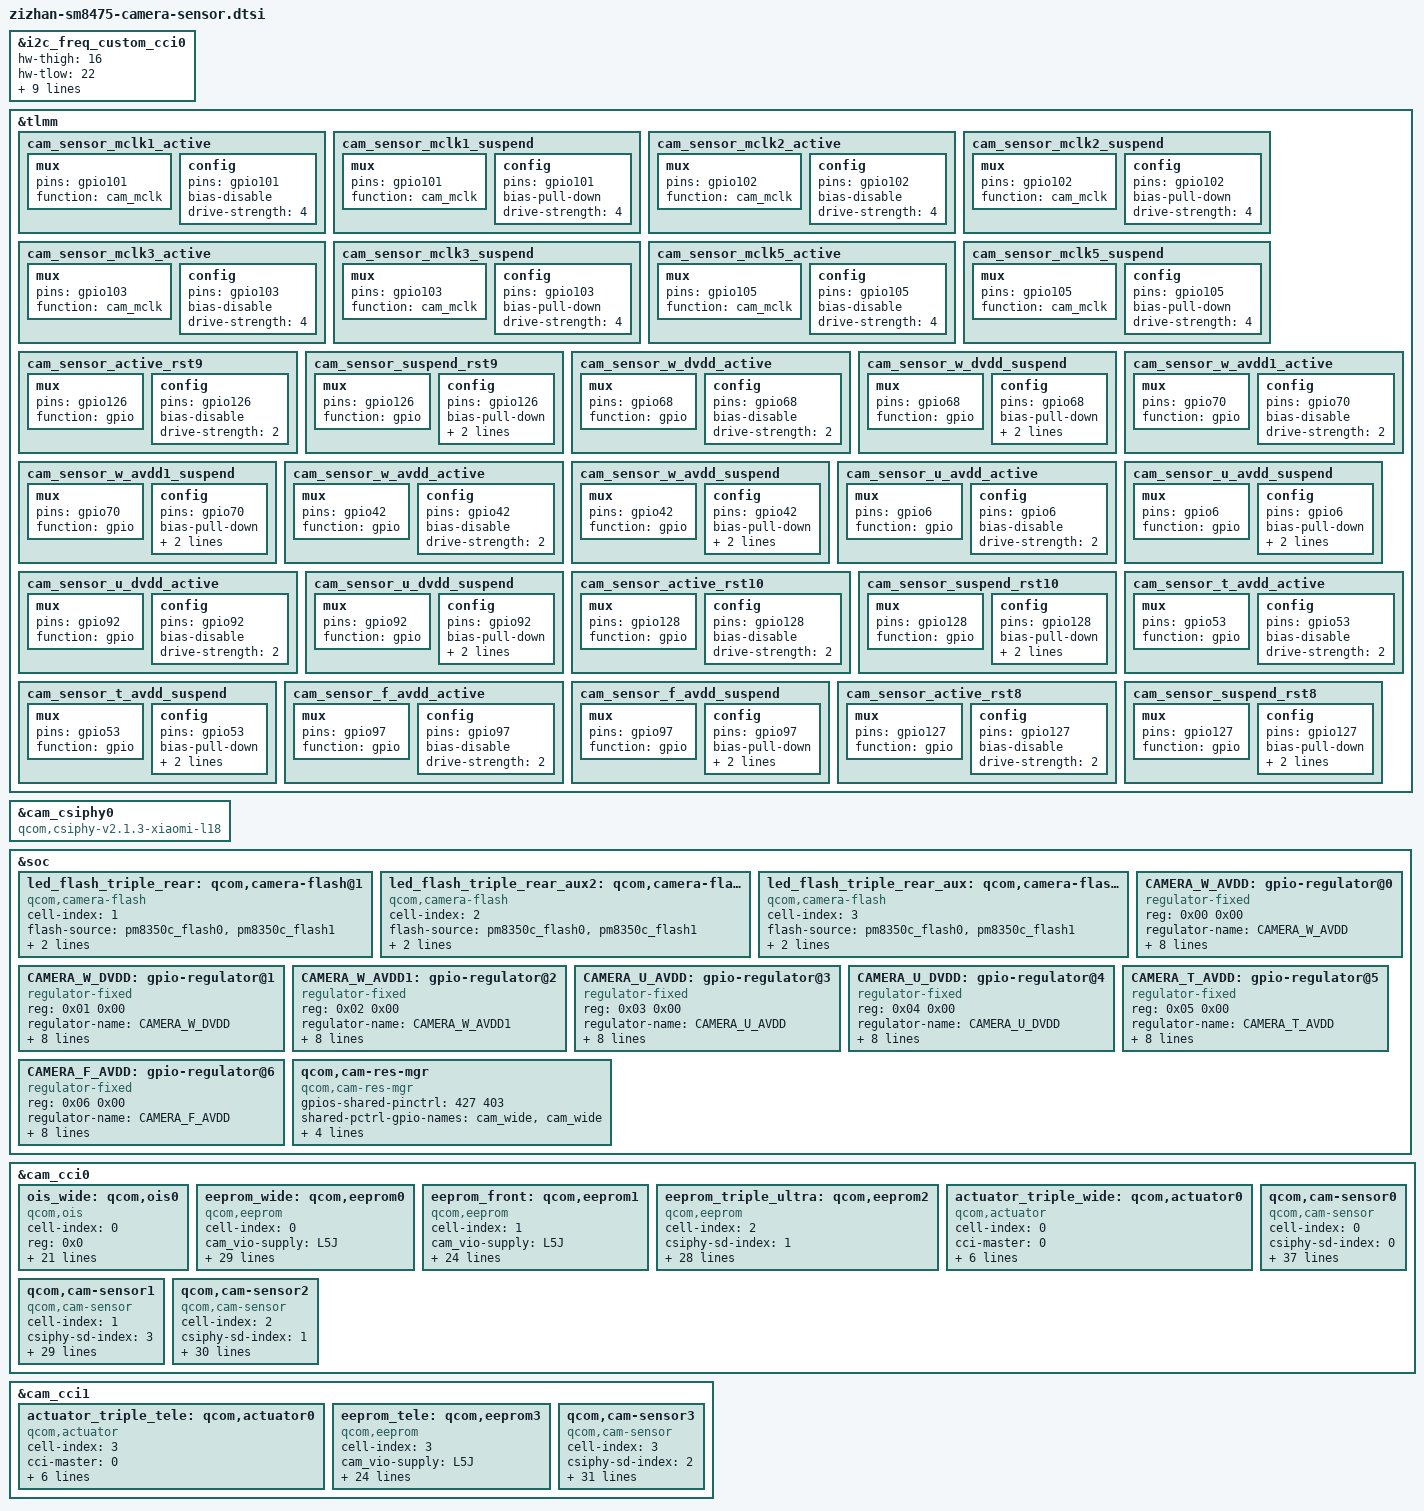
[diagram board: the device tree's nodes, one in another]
#include <dt-bindings/clock/qcom,camcc-waipio.h>

&i2c_freq_custom_cci0 {
	hw-thigh = <16>;
	hw-tlow = <22>;
	hw-tsu-sto = <17>;
	hw-tsu-sta = <18>;
	hw-thd-dat = <16>;
	hw-thd-sta = <15>;
	hw-tbuf = <24>;
	hw-scl-stretch-en = <1>;
	hw-trdhld = <3>;
	hw-tsp = <3>;
	cci-clk-src = <37500000>;
	status = "ok";
};

&tlmm {
//ultra
	cam_sensor_mclk1_active: cam_sensor_mclk1_active {
		/* MCLK1 */
		mux {
			pins = "gpio101";
			function = "cam_mclk";
		};

		config {
			pins = "gpio101";
			bias-disable; /* No PULL */
			drive-strength = <4>; /* 4 MA */
		};
	};

	cam_sensor_mclk1_suspend: cam_sensor_mclk1_suspend {
		/* MCLK1 */
		mux {
			pins = "gpio101";
			function = "cam_mclk";
		};

		config {
			pins = "gpio101";
			bias-pull-down; /* PULL DOWN */
			drive-strength = <4>; /* 4 MA */
		};
	};
//wide
	cam_sensor_mclk2_active: cam_sensor_mclk2_active {
		/* MCLK2 */
		mux {
			pins = "gpio102";
			function = "cam_mclk";
		};

		config {
			pins = "gpio102";
			bias-disable; /* No PULL */
			drive-strength = <4>; /* 4 MA */
		};
	};

	cam_sensor_mclk2_suspend: cam_sensor_mclk2_suspend {
		/* MCLK2 */
		mux {
			pins = "gpio102";
			function = "cam_mclk";
		};

		config {
			pins = "gpio102";
			bias-pull-down; /* PULL DOWN */
			drive-strength = <4>; /* 4 MA */
		};
	};
//tele
	cam_sensor_mclk3_active: cam_sensor_mclk3_active {
		/* MCLK3 */
		mux {
			pins = "gpio103";
			function = "cam_mclk";
		};

		config {
			pins = "gpio103";
			bias-disable; /* No PULL */
			drive-strength = <4>; /* 4 MA */
		};
	};

	cam_sensor_mclk3_suspend: cam_sensor_mclk3_suspend {
		/* MCLK3 */
		mux {
			pins = "gpio103";
			function = "cam_mclk";
		};

		config {
			pins = "gpio103";
			bias-pull-down; /* PULL DOWN */
			drive-strength = <4>; /* 4 MA */
		};
	};
//front
	cam_sensor_mclk5_active: cam_sensor_mclk5_active {
		/* MCLK5 */
		mux {
			pins = "gpio105";
			function = "cam_mclk";
		};

		config {
			pins = "gpio105";
			bias-disable; /* No PULL */
			drive-strength = <4>; /* 4 MA */
		};
	};

	cam_sensor_mclk5_suspend: cam_sensor_mclk5_suspend {
		/* MCLK5 */
		mux {
			pins = "gpio105";
			function = "cam_mclk";
		};

		config {
			pins = "gpio105";
			bias-pull-down; /* PULL DOWN */
			drive-strength = <4>; /* 4 MA */
		};
	};

//wide reset
	cam_sensor_active_rst9: cam_sensor_active_rst9 {
		/* RESET FRONT */
		mux {
			pins = "gpio126";
			function = "gpio";
		};

		config {
			pins = "gpio126";
			bias-disable; /* No PULL */
			drive-strength = <2>; /* 2 MA */
		};
	};

	cam_sensor_suspend_rst9: cam_sensor_suspend_rst9 {
		/* RESET FRONT */
		mux {
			pins = "gpio126";
			function = "gpio";
		};

		config {
			pins = "gpio126";
			bias-pull-down; /* PULL DOWN */
			drive-strength = <2>; /* 2 MA */
			output-low;
		};
	};

//wide dvdd
	cam_sensor_w_dvdd_active: cam_sensor_w_dvdd_active {
		/* SENSOR WIDE DVDD ENABLE */
		mux {
			pins = "gpio68";
			function = "gpio";
		};

		config {
			pins = "gpio68";
			bias-disable; /* No PULL */
			drive-strength = <2>; /* 2 MA */
		};
	};

	cam_sensor_w_dvdd_suspend: cam_sensor_w_dvdd_suspend {
		/* SENSOR WIDE DVDD DISABLE */
		mux {
			pins = "gpio68";
			function = "gpio";
		};

		config {
			pins = "gpio68";
			bias-pull-down; /* PULL DOWN */
			drive-strength = <2>; /* 2 MA */
			output-low;
		};
	};
//wide avdd1
	cam_sensor_w_avdd1_active: cam_sensor_w_avdd1_active {
		/* SENSOR WIDE DVDD ENABLE */
		mux {
			pins = "gpio70";
			function = "gpio";
		};

		config {
			pins = "gpio70";
			bias-disable; /* No PULL */
			drive-strength = <2>; /* 2 MA */
		};
	};

	cam_sensor_w_avdd1_suspend: cam_sensor_w_avdd1_suspend {
		/* SENSOR WIDE DVDD DISABLE */
		mux {
			pins = "gpio70";
			function = "gpio";
		};

		config {
			pins = "gpio70";
			bias-pull-down; /* PULL DOWN */
			drive-strength = <2>; /* 2 MA */
			output-low;
		};
	};

//wide avdd
	cam_sensor_w_avdd_active: cam_sensor_w_avdd_active {
		/* SENSOR WIDE DVDD ENABLE */
		mux {
			pins = "gpio42";
			function = "gpio";
		};

		config {
			pins = "gpio42";
			bias-disable; /* No PULL */
			drive-strength = <2>; /* 2 MA */
		};
	};

	cam_sensor_w_avdd_suspend: cam_sensor_w_avdd_suspend {
		/* SENSOR WIDE DVDD DISABLE */
		mux {
			pins = "gpio42";
			function = "gpio";
		};

		config {
			pins = "gpio42";
			bias-pull-down; /* PULL DOWN */
			drive-strength = <2>; /* 2 MA */
			output-low;
		};
	};

//ultra avdd
cam_sensor_u_avdd_active: cam_sensor_u_avdd_active {
		/* SENSOR WIDE DVDD ENABLE */
		mux {
			pins = "gpio6";
			function = "gpio";
		};

		config {
			pins = "gpio6";
			bias-disable; /* No PULL */
			drive-strength = <2>; /* 2 MA */
		};
	};

	cam_sensor_u_avdd_suspend: cam_sensor_u_avdd_suspend {
		/* SENSOR WIDE DVDD DISABLE */
		mux {
			pins = "gpio6";
			function = "gpio";
		};

		config {
			pins = "gpio6";
			bias-pull-down; /* PULL DOWN */
			drive-strength = <2>; /* 2 MA */
			output-low;
		};
	};

//ultra dvdd
cam_sensor_u_dvdd_active: cam_sensor_u_dvdd_active {
		/* SENSOR WIDE DVDD ENABLE */
		mux {
			pins = "gpio92";
			function = "gpio";
		};

		config {
			pins = "gpio92";
			bias-disable; /* No PULL */
			drive-strength = <2>; /* 2 MA */
		};
	};

	cam_sensor_u_dvdd_suspend: cam_sensor_u_dvdd_suspend {
		/* SENSOR WIDE DVDD DISABLE */
		mux {
			pins = "gpio92";
			function = "gpio";
		};

		config {
			pins = "gpio92";
			bias-pull-down; /* PULL DOWN */
			drive-strength = <2>; /* 2 MA */
			output-low;
		};
	};
//tele reset
	cam_sensor_active_rst10: cam_sensor_active_rst10 {
		/* RESET FRONT */
		mux {
			pins = "gpio128";
			function = "gpio";
		};

		config {
			pins = "gpio128";
			bias-disable; /* No PULL */
			drive-strength = <2>; /* 2 MA */
		};
	};

	cam_sensor_suspend_rst10: cam_sensor_suspend_rst10 {
		/* RESET FRONT */
		mux {
			pins = "gpio128";
			function = "gpio";
		};

		config {
			pins = "gpio128";
			bias-pull-down; /* PULL DOWN */
			drive-strength = <2>; /* 2 MA */
			output-low;
		};
	};
//tele avdd
	cam_sensor_t_avdd_active: cam_sensor_t_avdd_active {
		/* SENSOR WIDE DVDD ENABLE */
		mux {
			pins = "gpio53";
			function = "gpio";
		};

		config {
			pins = "gpio53";
			bias-disable; /* No PULL */
			drive-strength = <2>; /* 2 MA */
		};
	};

	cam_sensor_t_avdd_suspend: cam_sensor_t_avdd_suspend {
		/* SENSOR WIDE DVDD DISABLE */
		mux {
			pins = "gpio53";
			function = "gpio";
		};

		config {
			pins = "gpio53";
			bias-pull-down; /* PULL DOWN */
			drive-strength = <2>; /* 2 MA */
			output-low;
		};
	};

//front avdd
	cam_sensor_f_avdd_active: cam_sensor_f_avdd_active {
		/* SENSOR FRONT AVDD ENABLE */
		mux {
			pins = "gpio97";
			function = "gpio";
		};

		config {
			pins = "gpio97";
			bias-disable; /* No PULL */
			drive-strength = <2>; /* 2 MA */
		};
	};

	cam_sensor_f_avdd_suspend: cam_sensor_f_avdd_suspend {
		/* SENSOR FRONT AVDD DISABLE */
		mux {
			pins = "gpio97";
			function = "gpio";
		};

		config {
			pins = "gpio97";
			bias-pull-down; /* PULL DOWN */
			drive-strength = <2>; /* 2 MA */
			output-low;
		};
	};

//front reset
	cam_sensor_active_rst8: cam_sensor_active_rst8 {
		/* RESET FRONT */
		mux {
			pins = "gpio127";
			function = "gpio";
		};

		config {
			pins = "gpio127";
			bias-disable; /* No PULL */
			drive-strength = <2>; /* 2 MA */
		};
	};

	cam_sensor_suspend_rst8: cam_sensor_suspend_rst8 {
		/* RESET FRONT */
		mux {
			pins = "gpio127";
			function = "gpio";
		};

		config {
			pins = "gpio127";
			bias-pull-down; /* PULL DOWN */
			drive-strength = <2>; /* 2 MA */
			output-low;
		};
	};
};

&cam_csiphy0{
	compatible = "qcom,csiphy-v2.1.3-xiaomi-l18", "qcom,csiphy";
};

&soc {
	led_flash_triple_rear: qcom,camera-flash@1 {
		cell-index = <1>;
		compatible = "qcom,camera-flash";
		flash-source = <&pm8350c_flash0 &pm8350c_flash1>;
		torch-source = <&pm8350c_torch0 &pm8350c_torch1>;
		switch-source = <&pm8350c_switch2>;
		status = "ok";
	};

	led_flash_triple_rear_aux2: qcom,camera-flash@2 {
		cell-index = <2>;
		compatible = "qcom,camera-flash";
		flash-source = <&pm8350c_flash0 &pm8350c_flash1>;
		torch-source = <&pm8350c_torch0 &pm8350c_torch1>;
		switch-source = <&pm8350c_switch2>;
		status = "ok";
	};

	led_flash_triple_rear_aux: qcom,camera-flash@3 {
		cell-index = <3>;
		compatible = "qcom,camera-flash";
		flash-source = <&pm8350c_flash0 &pm8350c_flash1>;
		torch-source = <&pm8350c_torch0 &pm8350c_torch1>;
		switch-source = <&pm8350c_switch2>;
		status = "ok";
	};

	CAMERA_W_AVDD: gpio-regulator@0 {
		compatible = "regulator-fixed";
		reg = <0x00 0x00>;
		regulator-name = "CAMERA_W_AVDD";
		regulator-min-microvolt = <2800000>;
		regulator-max-microvolt = <2800000>;
		regulator-enable-ramp-delay = <100>;
		enable-active-high;
		gpio = <&tlmm 42 0>;
		pinctrl-names = "default", "sleep";
		pinctrl-0 = <&cam_sensor_w_avdd_active &cam_sensor_w_avdd_suspend>;
		vin-supply = <&BOB>;
	};


	CAMERA_W_DVDD: gpio-regulator@1 {
		compatible = "regulator-fixed";
		reg = <0x01 0x00>;
		regulator-name = "CAMERA_W_DVDD";
		regulator-min-microvolt = <1104000>;
		regulator-max-microvolt = <1104000>;
		regulator-enable-ramp-delay = <100>;
		enable-active-high;
		gpio = <&tlmm 68 0>;
		pinctrl-names = "default", "sleep";
		pinctrl-0 = <&cam_sensor_w_dvdd_active &cam_sensor_w_dvdd_suspend>;
		vin-supply = <&S12B>;
	};

	CAMERA_W_AVDD1: gpio-regulator@2 {
		compatible = "regulator-fixed";
		reg = <0x02 0x00>;
		regulator-name = "CAMERA_W_AVDD1";
		regulator-min-microvolt = <1800000>;
		regulator-max-microvolt = <1800000>;
		regulator-enable-ramp-delay = <100>;
		enable-active-high;
		gpio = <&tlmm 70 0>;
		pinctrl-names = "default", "sleep";
		pinctrl-0 = <&cam_sensor_w_avdd1_active &cam_sensor_w_avdd1_suspend>;
		vin-supply = <&S1C>;
	};

	CAMERA_U_AVDD: gpio-regulator@3 {
		compatible = "regulator-fixed";
		reg = <0x03 0x00>;
		regulator-name = "CAMERA_U_AVDD";
		regulator-min-microvolt = <2800000>;
		regulator-max-microvolt = <2800000>;
		regulator-enable-ramp-delay = <100>;
		enable-active-high;
		gpio = <&tlmm 6 0>;
		pinctrl-names = "default", "sleep";
		pinctrl-0 = <&cam_sensor_u_avdd_active &cam_sensor_u_avdd_suspend>;
		vin-supply = <&BOB>;
	};

	CAMERA_U_DVDD: gpio-regulator@4 {
		compatible = "regulator-fixed";
		reg = <0x04 0x00>;
		regulator-name = "CAMERA_U_DVDD";
		regulator-min-microvolt = <1200000>;
		regulator-max-microvolt = <1200000>;
		regulator-enable-ramp-delay = <100>;
		enable-active-high;
		gpio = <&tlmm 92 0>;
		pinctrl-names = "default", "sleep";
		pinctrl-0 = <&cam_sensor_u_dvdd_active &cam_sensor_u_dvdd_suspend>;
		vin-supply = <&S12B>;
	};

	CAMERA_T_AVDD: gpio-regulator@5 {
		compatible = "regulator-fixed";
		reg = <0x05 0x00>;
		regulator-name = "CAMERA_T_AVDD";
		regulator-min-microvolt = <2800000>;
		regulator-max-microvolt = <2800000>;
		regulator-enable-ramp-delay = <100>;
		enable-active-high;
		gpio = <&tlmm 53 0>;
		pinctrl-names = "default", "sleep";
		pinctrl-0 = <&cam_sensor_t_avdd_active &cam_sensor_t_avdd_suspend>;
		vin-supply = <&BOB>;
	};

	CAMERA_F_AVDD: gpio-regulator@6 {
		compatible = "regulator-fixed";
		reg = <0x06 0x00>;
		regulator-name = "CAMERA_F_AVDD";
		regulator-min-microvolt = <2900000>;
		regulator-max-microvolt = <2900000>;
		regulator-enable-ramp-delay = <100>;
		enable-active-high;
		gpio = <&tlmm 97 0>;
		pinctrl-names = "default", "sleep";
		pinctrl-0 = <&cam_sensor_f_avdd_active &cam_sensor_f_avdd_suspend>;
		vin-supply = <&BOB>;
	};


	//GPIO1 -> 302
	qcom,cam-res-mgr {
		compatible = "qcom,cam-res-mgr";
		gpios-shared-pinctrl = <427 403>;
		shared-pctrl-gpio-names = "cam_wide", "cam_wide";
		pinctrl-names = "cam_wide_active", "cam_wide_suspend";
		pinctrl-0 = <&cam_sensor_active_rst9
				&cam_sensor_mclk2_active>;
		pinctrl-1 = <&cam_sensor_suspend_rst9
				&cam_sensor_mclk2_suspend>;
		status = "ok";
	};
};

&cam_cci0
{
	ois_wide: qcom,ois0 {
		cell-index = <0>;
		reg = <0x0>;
		compatible = "qcom,ois";
		cam_vio-supply = <&L5J>;
		cam_clk-supply = <&cam_cc_titan_top_gdsc>;
		cam_v_custom2-supply = <&L4J>;
		regulator-names = "cam_vio", "cam_clk", "cam_v_custom2";
		rgltr-cntrl-support;
		rgltr-min-voltage = <1800000 0 3104000>;
		rgltr-max-voltage = <1800000 0 3104000>;
		rgltr-load-current = <5000 0 103000>;
		use-shared-clk;
		gpio-no-mux = <0>;
		gpios = <&tlmm 102 0>,
			<&tlmm 126 0>;
		gpio-reset = <1>;
		gpio-req-tbl-num = <0 1>;
		gpio-req-tbl-flags = <1 0>;
		gpio-req-tbl-label = "CAMIF_MCLK2",
					"CAM_RESET9";
		cci-device = <0>;
		cci-master = <0>;
		clocks = <&clock_camcc CAM_CC_MCLK2_CLK>;
		clock-names = "cam_clk";
		clock-cntl-level = "nominal";
		clock-rates = <19200000>;
		status = "ok";
	};

	////wide imx766
	eeprom_wide: qcom,eeprom0 {
		cell-index = <0>;
		compatible = "qcom,eeprom";
		cam_vio-supply = <&L5J>;
		cam_vdig-supply = <&CAMERA_W_DVDD>;
		cam_clk-supply = <&cam_cc_titan_top_gdsc>;
		cam_vana-supply = <&CAMERA_W_AVDD>;
		cam_v_custom1-supply = <&CAMERA_W_AVDD1>;
		cam_v_custom2-supply = <&L4J>;   //OIS VCC
		cam_vaf-supply = <&L3J>;
		cam_vana1-supply = <&S12B>;
		regulator-names = "cam_vio", "cam_vdig",
			"cam_clk", "cam_vana", "cam_v_custom1", "cam_v_custom2", "cam_vaf", "cam_vana1";
		rgltr-cntrl-support;
		rgltr-min-voltage = <1800000 1104000 0 2800000 1800000 3104000 3104000 1224000>;
		rgltr-max-voltage = <1800000 1104000 0 2800000 1800000 3104000 3104000 1400000>;
		rgltr-load-current = <5000 653600 0 57500 6000 103000 120000 2356666>;
		use-shared-clk;
		gpio-no-mux = <0>;
		gpios = <&tlmm 102 0>,
			<&tlmm 126 0>;
		gpio-reset = <1>;
		gpio-req-tbl-num = <0 1>;
		gpio-req-tbl-flags = <1 0>;
		gpio-req-tbl-label = "CAMIF_MCLK2",
					"CAM_RESET9";
		cci-device = <0>;
		cci-master = <0>;
		clocks = <&clock_camcc CAM_CC_MCLK2_CLK>;
		clock-names = "cam_clk";
		clock-cntl-level = "nominal";
		clock-rates = <19200000>;
		status = "ok";
	};

	//front imx596
	eeprom_front: qcom,eeprom1 {
		cell-index = <1>;
		compatible = "qcom,eeprom";
		cam_vio-supply = <&L5J>;
		cam_vdig-supply = <&L2J>;
		cam_clk-supply = <&cam_cc_titan_top_gdsc>;
		cam_vana-supply = <&CAMERA_F_AVDD>;
		regulator-names = "cam_vio", "cam_vdig", "cam_clk", "cam_vana";
		rgltr-cntrl-support;
		rgltr-min-voltage = <1800000 1152000 0 2900000>;
		rgltr-max-voltage = <1800000 1152000 0 2900000>;
		rgltr-load-current = <56000 24000 0 35000>;
		gpio-no-mux = <0>;
		pinctrl-names = "cam_default", "cam_suspend";
		pinctrl-0 = <&cam_sensor_mclk5_active
			&cam_sensor_active_rst8>;
		pinctrl-1 = <&cam_sensor_mclk5_suspend
			&cam_sensor_suspend_rst8>;
		gpios = <&tlmm 105 0>,
			<&tlmm 127 0>;
		gpio-reset = <1>;
		gpio-req-tbl-num = <0 1>;
		gpio-req-tbl-flags = <1 0>;
		gpio-req-tbl-label = "CAMIF_MCLK5", "CAM_RESET8";
		cci-device = <0>;
		cci-master = <1>;
		clocks = <&clock_camcc CAM_CC_MCLK5_CLK>;
		clock-names = "cam_clk";
		clock-cntl-level = "nominal";
		clock-rates = <19200000>;
		status = "ok";
	};

	//ultra ov13b10
	eeprom_triple_ultra: qcom,eeprom2 {
		cell-index = <2>;
		compatible = "qcom,eeprom";
		csiphy-sd-index = <1>;
		sensor-position-roll = <90>;
		sensor-position-pitch = <0>;
		sensor-position-yaw = <180>;
		cam_vio-supply = <&L5J>;
		cam_vdig-supply = <&CAMERA_U_DVDD>;
		cam_clk-supply = <&cam_cc_titan_top_gdsc>;
		cam_vana-supply = <&CAMERA_U_AVDD>;
		regulator-names = "cam_vio", "cam_vdig",
			"cam_clk", "cam_vana";
		rgltr-cntrl-support;
		rgltr-min-voltage = <1800000 1200000 0 2800000>;
		rgltr-max-voltage = <1800000 1200000 0 2800000>;
		rgltr-load-current = <400 78000 0 35700>;
		gpio-no-mux = <0>;
		pinctrl-names = "cam_default", "cam_suspend";
		pinctrl-0 = <&cam_sensor_mclk1_active
			&cam_sensor_active_rst1>;
		pinctrl-1 = <&cam_sensor_mclk1_suspend
			&cam_sensor_suspend_rst1>;
		gpios = <&tlmm 101 0>,
			<&tlmm 24 0>;
		gpio-reset = <1>;
		gpio-req-tbl-num = <0 1>;
		gpio-req-tbl-flags = <1 0>;
		gpio-req-tbl-label = "CAMIF_MCLK1",
					"CAM_RESET1";
		cci-device = <0>;
		cci-master = <1>;
		clocks = <&clock_camcc CAM_CC_MCLK1_CLK>;
		clock-names = "cam_clk";
		clock-cntl-level = "nominal";
		clock-rates = <19200000>;
		status = "ok";
	};

	actuator_triple_wide: qcom,actuator0 {
		cell-index = <0>;
		compatible = "qcom,actuator";
		cci-master = <0>;
		cam_vaf-supply = <&L3J>;
		regulator-names = "cam_vaf";
		rgltr-cntrl-support;
		rgltr-min-voltage = <3104000>;
		rgltr-max-voltage = <3104000>;
		rgltr-load-current = <120000>;
	};

	//wide imx766
	qcom,cam-sensor0 {
		cell-index = <0>;
		compatible = "qcom,cam-sensor";
		csiphy-sd-index = <0>;
		eeprom-src = <&eeprom_wide>;
		actuator-src = <&actuator_triple_wide>;
		ois-src  = <&ois_wide>;
		led-flash-src = <&led_flash_triple_rear>;
		sensor-position-roll = <90>;
		sensor-position-pitch = <0>;
		sensor-position-yaw = <180>;
		cam_vio-supply = <&L5J>;
		cam_vdig-supply = <&CAMERA_W_DVDD>;
		cam_clk-supply = <&cam_cc_titan_top_gdsc>;
		cam_vana-supply = <&CAMERA_W_AVDD>;
		cam_v_custom1-supply = <&CAMERA_W_AVDD1>;
		cam_v_custom2-supply = <&L4J>;   //OIS VCC
		cam_vaf-supply = <&L3J>;
		cam_vana1-supply = <&S12B>;
		regulator-names = "cam_vio", "cam_vdig",
			"cam_clk", "cam_vana", "cam_v_custom1", "cam_v_custom2", "cam_vaf", "cam_vana1";
		rgltr-cntrl-support;
		rgltr-min-voltage = <1800000 1104000 0 2800000 1800000 3104000 3104000 1224000>;
		rgltr-max-voltage = <1800000 1104000 0 2800000 1800000 3104000 3104000 1400000>;
		rgltr-load-current = <5000 653600 0 57500 6000 103000 120000 2356666>;
		use-shared-clk;
		gpio-no-mux = <0>;
		gpios = <&tlmm 102 0>,
			<&tlmm 126 0>;
		gpio-reset = <1>;
		gpio-req-tbl-num = <0 1>;
		gpio-req-tbl-flags = <1 0>;
		gpio-req-tbl-label = "CAMIF_MCLK2",
					"CAM_RESET9";
		cci-device = <0>;
		cci-master = <0>;
		clocks = <&clock_camcc CAM_CC_MCLK2_CLK>;
		clock-names = "cam_clk";
		clock-cntl-level = "nominal";
		clock-rates = <19200000>;
		status = "ok";
	};

	//front imx596
	qcom,cam-sensor1 {
		cell-index = <1>;
		compatible = "qcom,cam-sensor";
		csiphy-sd-index = <3>;
		eeprom-src = <&eeprom_front>;
		sensor-position-roll = <270>;
		sensor-position-pitch = <0>;
		sensor-position-yaw = <0>;
		cam_vio-supply = <&L5J>;
		cam_vdig-supply = <&L2J>;
		cam_clk-supply = <&cam_cc_titan_top_gdsc>;
		cam_vana-supply = <&CAMERA_F_AVDD>;
		regulator-names = "cam_vio", "cam_vdig", "cam_clk", "cam_vana";
		rgltr-cntrl-support;
		rgltr-min-voltage = <1800000 1152000 0 2900000>;
		rgltr-max-voltage = <1800000 1152000 0 2900000>;
		rgltr-load-current = <56000 24000 0 35000>;
		gpio-no-mux = <0>;
		pinctrl-names = "cam_default", "cam_suspend";
		pinctrl-0 = <&cam_sensor_mclk5_active
			&cam_sensor_active_rst8>;
		pinctrl-1 = <&cam_sensor_mclk5_suspend
			&cam_sensor_suspend_rst8>;
		gpios = <&tlmm 105 0>,
			<&tlmm 127 0>;
		gpio-reset = <1>;
		gpio-req-tbl-num = <0 1>;
		gpio-req-tbl-flags = <1 0>;
		gpio-req-tbl-label = "CAMIF_MCLK5", "CAM_RESET8";
		cci-device = <0>;
		cci-master = <1>;
		clocks = <&clock_camcc CAM_CC_MCLK5_CLK>;
		clock-names = "cam_clk";
		clock-cntl-level = "nominal";
		clock-rates = <19200000>;
		status = "ok";
	};

	//ultra ov13b10
	qcom,cam-sensor2 {
		cell-index = <2>;
		compatible = "qcom,cam-sensor";
		csiphy-sd-index = <1>;
		eeprom-src = <&eeprom_triple_ultra>;
		led-flash-src = <&led_flash_triple_rear_aux2>;
		sensor-position-roll = <90>;
		sensor-position-pitch = <0>;
		sensor-position-yaw = <180>;
		cam_vio-supply = <&L5J>;
		cam_vdig-supply = <&CAMERA_U_DVDD>;
		cam_clk-supply = <&cam_cc_titan_top_gdsc>;
		cam_vana-supply = <&CAMERA_U_AVDD>;
		//cam_v_custom1-supply = <&L7J>;
		regulator-names = "cam_vio", "cam_vdig",
			"cam_clk", "cam_vana";
		rgltr-cntrl-support;
		rgltr-min-voltage = <1800000 1200000 0 2800000>;
		rgltr-max-voltage = <1800000 1200000 0 2800000>;
		rgltr-load-current = <400 78000 0 35700>;
		gpio-no-mux = <0>;
		pinctrl-names = "cam_default", "cam_suspend";
		pinctrl-0 = <&cam_sensor_mclk1_active
			&cam_sensor_active_rst1>;
		pinctrl-1 = <&cam_sensor_mclk1_suspend
			&cam_sensor_suspend_rst1>;
		gpios = <&tlmm 101 0>,
			<&tlmm 24 0>;
		gpio-reset = <1>;
		gpio-req-tbl-num = <0 1>;
		gpio-req-tbl-flags = <1 0>;
		gpio-req-tbl-label = "CAMIF_MCLK1",
					"CAM_RESET1";
		cci-device = <0>;
		cci-master = <1>;
		clocks = <&clock_camcc CAM_CC_MCLK1_CLK>;
		clock-names = "cam_clk";
		clock-cntl-level = "nominal";
		clock-rates = <19200000>;
		status = "ok";
	};

};

&cam_cci1 {
	actuator_triple_tele: qcom,actuator0 {
		cell-index = <3>;
		compatible = "qcom,actuator";
		cci-master = <0>;
		cam_vaf-supply = <&L7J>;
		regulator-names = "cam_vaf";
		rgltr-cntrl-support;
		rgltr-min-voltage = <3104000>;
		rgltr-max-voltage = <3104000>;
		rgltr-load-current = <120000>;
	};

	//tele imx663T
	eeprom_tele: qcom,eeprom3 {
		cell-index = <3>;
		compatible = "qcom,eeprom";
		cam_vio-supply = <&L5J>;
		cam_vdig-supply = <&L1J>;
		cam_clk-supply = <&cam_cc_titan_top_gdsc>;
		cam_vana-supply = <&CAMERA_T_AVDD>;
		regulator-names = "cam_vio", "cam_vdig",
			"cam_clk", "cam_vana";
		rgltr-cntrl-support;
		rgltr-min-voltage = <1800000 1056000 0 2800000>;
		rgltr-max-voltage = <1800000 1056000 0 2800000>;
		rgltr-load-current = <5000 653600 0 57500>;
		gpio-no-mux = <0>;
		pinctrl-names = "cam_default", "cam_suspend";
		pinctrl-0 = <&cam_sensor_mclk3_active
			&cam_sensor_active_rst10>;
		pinctrl-1 = <&cam_sensor_mclk3_suspend
			&cam_sensor_suspend_rst10>;
		gpios = <&tlmm 103 0>,
			<&tlmm 128 0>;
		gpio-reset = <1>;
		gpio-req-tbl-num = <0 1>;
		gpio-req-tbl-flags = <1 0>;
		gpio-req-tbl-label = "CAMIF_MCLK3",
					"CAM_RESET10";
		cci-device = <1>;
		cci-master = <0>;
		clocks = <&clock_camcc CAM_CC_MCLK3_CLK>;
		clock-names = "cam_clk";
		clock-cntl-level = "nominal";
		clock-rates = <19200000>;
		status = "ok";
	};
	//tele imx663T
	qcom,cam-sensor3 {
		cell-index = <3>;
		compatible = "qcom,cam-sensor";
		csiphy-sd-index = <2>;
		eeprom-src = <&eeprom_tele>;
		led-flash-src = <&led_flash_triple_rear_aux>;
		actuator-src = <&actuator_triple_tele>;
		sensor-position-roll = <90>;
		sensor-position-pitch = <0>;
		sensor-position-yaw = <180>;
		cam_vio-supply = <&L5J>;
		cam_vdig-supply = <&L1J>;
		cam_clk-supply = <&cam_cc_titan_top_gdsc>;
		cam_vana-supply = <&CAMERA_T_AVDD>;
		//cam_v_custom1-supply = <&L7J>;
		regulator-names = "cam_vio", "cam_vdig",
			"cam_clk", "cam_vana";
		rgltr-cntrl-support;
		rgltr-min-voltage = <1800000 1056000 0 2800000>;
		rgltr-max-voltage = <1800000 1056000 0 2800000>;
		rgltr-load-current = <5000 653600 0 57500>;
		gpio-no-mux = <0>;
		pinctrl-names = "cam_default", "cam_suspend";
		pinctrl-0 = <&cam_sensor_mclk3_active
			&cam_sensor_active_rst10>;
		pinctrl-1 = <&cam_sensor_mclk3_suspend
			&cam_sensor_suspend_rst10>;
		gpios = <&tlmm 103 0>,
			<&tlmm 128 0>;
		gpio-reset = <1>;
		gpio-req-tbl-num = <0 1>;
		gpio-req-tbl-flags = <1 0>;
		gpio-req-tbl-label = "CAMIF_MCLK3",
					"CAM_RESET10";
		cci-device = <1>;
		cci-master = <0>;
		clocks = <&clock_camcc CAM_CC_MCLK3_CLK>;
		clock-names = "cam_clk";
		clock-cntl-level = "nominal";
		clock-rates = <19200000>;
		status = "ok";
	};
};
